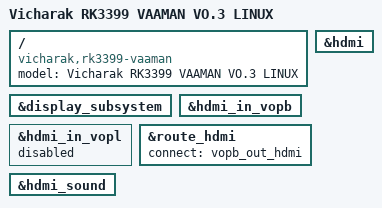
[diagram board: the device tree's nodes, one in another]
// SPDX-License-Identifier: (GPL-2.0+ OR MIT)
/*
 * Copyright (C) 2023 Vicharak Computers LLP
 */

/dts-v1/;

#include "rk3399-vaaman.dtsi"
#include "rk3399-linux.dtsi"

/ {
	model = "Vicharak RK3399 VAAMAN VO.3 LINUX";
	compatible = "vicharak,rk3399-vaaman", "rockchip,rk3399";
};

&display_subsystem {
	status = "okay";
};

&hdmi {
	status = "okay";
};

&hdmi_in_vopb {
	status = "okay";
};

&hdmi_in_vopl {
	status = "disabled";
};

&route_hdmi {
	connect = <&vopb_out_hdmi>;
	status = "okay";
};

&hdmi_sound {
	status = "okay";
};
